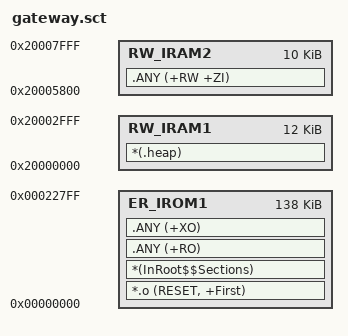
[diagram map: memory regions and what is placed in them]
; *************************************************************
; *** Scatter-Loading Description File for Gateway (with BLE) ***
; *** RAM1: FreeRTOS heap 12KB, RAM2: global/static 10KB      ***
; *** BLE reserved in middle (0x20003000-0x20005FFF)          ***
; *************************************************************

LR_IROM1 0x00000000 0x00022800  {
  ER_IROM1 0x00000000 0x00022800  {
    *.o (RESET, +First)
    *(InRoot$$Sections)
    .ANY (+RO)
    .ANY (+XO)
  }

  RW_IRAM1 0x20000000 0x00003000  {
    *(.heap)
  }

  RW_IRAM2 0x20005800 0x00002800  {
    .ANY (+RW +ZI)
  }
}
